# CBASS_CBASS_QOS_45D20000h register map
Vendor: Texas Instruments
Peripheral module from a debugger description file (folder AM275x).
Registers are 32-bit, read-write, reset 0x0 unless marked. A register's access mark holds for its fields unless they carry their own. Offsets are as the file gives them; lines under a group give offsets from that group; [hi:lo] are bit positions; {n}, {i} and the like mark numbered series; 'fields as' and 'values as' point back to an identical list; <NAME> marks a mode.

## cbass_qos
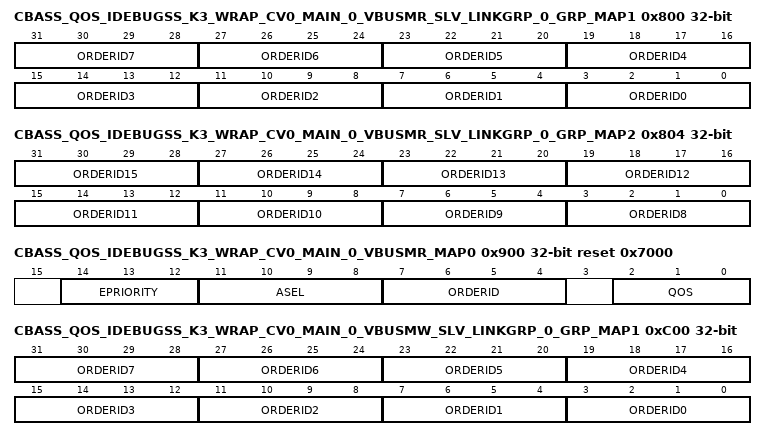
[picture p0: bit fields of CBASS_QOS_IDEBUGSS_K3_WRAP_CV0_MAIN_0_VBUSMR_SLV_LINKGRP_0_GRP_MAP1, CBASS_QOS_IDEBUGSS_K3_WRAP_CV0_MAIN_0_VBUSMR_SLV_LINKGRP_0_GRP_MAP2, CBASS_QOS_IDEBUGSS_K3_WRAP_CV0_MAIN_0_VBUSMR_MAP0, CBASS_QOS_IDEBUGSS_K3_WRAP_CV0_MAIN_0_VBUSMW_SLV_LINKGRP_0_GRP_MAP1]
0x800 CBASS_QOS_IDEBUGSS_K3_WRAP_CV0_MAIN_0_VBUSMR_SLV_LINKGRP_0_GRP_MAP1 — The Group Map Register defines the final orderid for the initiator Idebugss_k3_wrap_cv0_main_0.vbusmr for group slv_linkgrp_0.
  [4n+3:4n] ORDERID{n} (n=0..7) — orderid signal for {n}. Reset Source: domain_default_rst_mod_g_rst_n
0x804 CBASS_QOS_IDEBUGSS_K3_WRAP_CV0_MAIN_0_VBUSMR_SLV_LINKGRP_0_GRP_MAP2 — The Group Map Register defines the final orderid for the initiator Idebugss_k3_wrap_cv0_main_0.vbusmr for group slv_linkgrp_0.
  [4n-29:4n-32] ORDERID{n} (n=8..15) — orderid signal for {n}. Reset Source: domain_default_rst_mod_g_rst_n
0x900 CBASS_QOS_IDEBUGSS_K3_WRAP_CV0_MAIN_0_VBUSMR_MAP0 reset 0x7000 — The Map Register defines the fields for the initiator DEBUGSS0 Read Port per channel
  [14:12] EPRIORITY — epriority signal for channel N.This is the strict priority arbitration priority at the destination Reset Source: domain_default_rst_mod_g_rst_n
  [11:8] ASEL — Only used for PCIe, and cache coherency with A53 ACP. So traffic to MSRAM or DDR with asel set to below values will be routed via A53 cache controller. ASEL=0 | normalASEL=1 | PCIe address space for the entire addressASEL=14 | W | cause L2 cache allocation: for cache warming featureASEL=14 | R | does not cause L2 cache allocationASEL=15 | R/W | does not cause L2 cache allocation Reset Source: domain_default_rst_mod_g_rst_n
  [7:4] ORDERID — orderid signal for channel N.Selects to route for load balancing (0-7 uses one route, 8-15 another).Also used by DDR4/LPDDR4 re-ordering to maximize throughput. Order of transactions is only guaranteed with the same orderid Reset Source: domain_default_rst_mod_g_rst_n
  [2:0] QOS — qos signal for channel N. Reset Source: domain_default_rst_mod_g_rst_n
0xC00 CBASS_QOS_IDEBUGSS_K3_WRAP_CV0_MAIN_0_VBUSMW_SLV_LINKGRP_0_GRP_MAP1 — The Group Map Register defines the final orderid for the initiator Idebugss_k3_wrap_cv0_main_0.vbusmw for group slv_linkgrp_0.
  fields as CBASS_QOS_IDEBUGSS_K3_WRAP_CV0_MAIN_0_VBUSMR_SLV_LINKGRP_0_GRP_MAP1
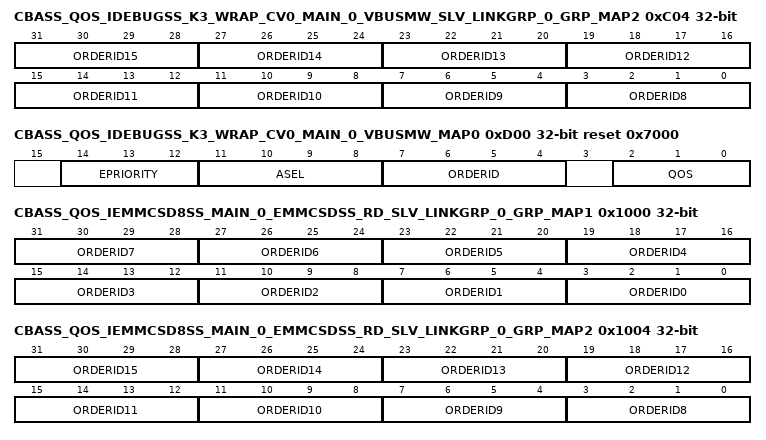
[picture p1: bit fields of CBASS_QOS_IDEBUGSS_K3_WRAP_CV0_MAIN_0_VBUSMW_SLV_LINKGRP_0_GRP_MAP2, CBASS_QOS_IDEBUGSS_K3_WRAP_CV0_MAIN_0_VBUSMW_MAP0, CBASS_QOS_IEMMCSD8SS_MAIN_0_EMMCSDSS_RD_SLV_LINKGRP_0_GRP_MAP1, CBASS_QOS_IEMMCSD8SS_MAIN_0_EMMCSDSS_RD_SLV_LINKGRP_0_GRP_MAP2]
0xC04 CBASS_QOS_IDEBUGSS_K3_WRAP_CV0_MAIN_0_VBUSMW_SLV_LINKGRP_0_GRP_MAP2 — The Group Map Register defines the final orderid for the initiator Idebugss_k3_wrap_cv0_main_0.vbusmw for group slv_linkgrp_0.
  fields as CBASS_QOS_IDEBUGSS_K3_WRAP_CV0_MAIN_0_VBUSMR_SLV_LINKGRP_0_GRP_MAP2
0xD00 CBASS_QOS_IDEBUGSS_K3_WRAP_CV0_MAIN_0_VBUSMW_MAP0 reset 0x7000 — The Map Register defines the fields for the initiator DEBUGSS0 Write Port per channel
  fields as CBASS_QOS_IDEBUGSS_K3_WRAP_CV0_MAIN_0_VBUSMR_MAP0
0x1000 CBASS_QOS_IEMMCSD8SS_MAIN_0_EMMCSDSS_RD_SLV_LINKGRP_0_GRP_MAP1 — The Group Map Register defines the final orderid for the initiator Iemmcsd8ss_main_0.emmcsdss_rd for group slv_linkgrp_0.
  fields as CBASS_QOS_IDEBUGSS_K3_WRAP_CV0_MAIN_0_VBUSMR_SLV_LINKGRP_0_GRP_MAP1
0x1004 CBASS_QOS_IEMMCSD8SS_MAIN_0_EMMCSDSS_RD_SLV_LINKGRP_0_GRP_MAP2 — The Group Map Register defines the final orderid for the initiator Iemmcsd8ss_main_0.emmcsdss_rd for group slv_linkgrp_0.
  fields as CBASS_QOS_IDEBUGSS_K3_WRAP_CV0_MAIN_0_VBUSMR_SLV_LINKGRP_0_GRP_MAP2
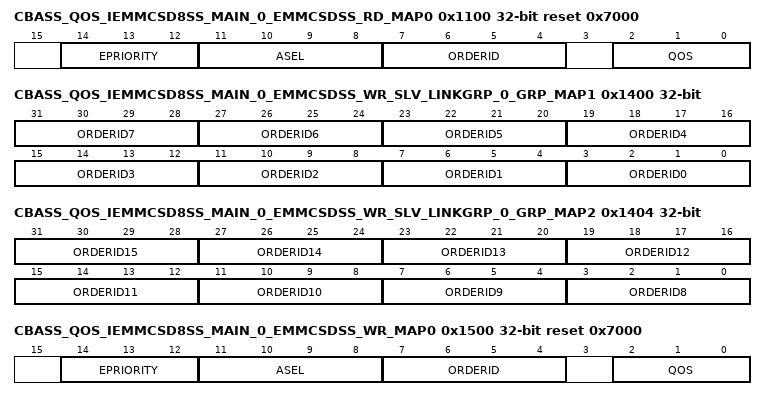
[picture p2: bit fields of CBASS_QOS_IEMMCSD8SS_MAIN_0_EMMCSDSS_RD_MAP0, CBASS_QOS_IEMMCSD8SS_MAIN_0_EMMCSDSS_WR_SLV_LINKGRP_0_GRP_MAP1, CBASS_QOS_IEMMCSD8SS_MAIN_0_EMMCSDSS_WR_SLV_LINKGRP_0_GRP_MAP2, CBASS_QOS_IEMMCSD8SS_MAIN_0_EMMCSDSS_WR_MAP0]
0x1100 CBASS_QOS_IEMMCSD8SS_MAIN_0_EMMCSDSS_RD_MAP0 reset 0x7000 — The Map Register defines the fields for the initiator MMCSD0 Read Port per channel
  fields as CBASS_QOS_IDEBUGSS_K3_WRAP_CV0_MAIN_0_VBUSMR_MAP0
0x1400 CBASS_QOS_IEMMCSD8SS_MAIN_0_EMMCSDSS_WR_SLV_LINKGRP_0_GRP_MAP1 — The Group Map Register defines the final orderid for the initiator Iemmcsd8ss_main_0.emmcsdss_wr for group slv_linkgrp_0.
  fields as CBASS_QOS_IDEBUGSS_K3_WRAP_CV0_MAIN_0_VBUSMR_SLV_LINKGRP_0_GRP_MAP1
0x1404 CBASS_QOS_IEMMCSD8SS_MAIN_0_EMMCSDSS_WR_SLV_LINKGRP_0_GRP_MAP2 — The Group Map Register defines the final orderid for the initiator Iemmcsd8ss_main_0.emmcsdss_wr for group slv_linkgrp_0.
  fields as CBASS_QOS_IDEBUGSS_K3_WRAP_CV0_MAIN_0_VBUSMR_SLV_LINKGRP_0_GRP_MAP2
0x1500 CBASS_QOS_IEMMCSD8SS_MAIN_0_EMMCSDSS_WR_MAP0 reset 0x7000 — The Map Register defines the fields for the initiator MMCSD0 Write Port per channel
  fields as CBASS_QOS_IDEBUGSS_K3_WRAP_CV0_MAIN_0_VBUSMR_MAP0
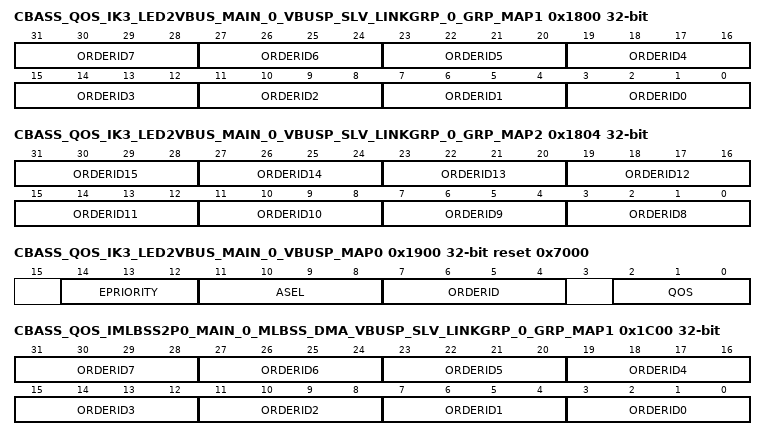
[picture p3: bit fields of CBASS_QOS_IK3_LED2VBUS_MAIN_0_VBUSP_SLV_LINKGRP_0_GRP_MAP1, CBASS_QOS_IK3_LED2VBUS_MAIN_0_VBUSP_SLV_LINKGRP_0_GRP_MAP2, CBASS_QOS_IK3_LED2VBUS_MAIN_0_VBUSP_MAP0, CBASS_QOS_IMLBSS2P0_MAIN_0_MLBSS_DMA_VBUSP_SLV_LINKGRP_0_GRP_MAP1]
0x1800 CBASS_QOS_IK3_LED2VBUS_MAIN_0_VBUSP_SLV_LINKGRP_0_GRP_MAP1 — The Group Map Register defines the final orderid for the initiator Ik3_led2vbus_main_0.vbusp for group slv_linkgrp_0.
  fields as CBASS_QOS_IDEBUGSS_K3_WRAP_CV0_MAIN_0_VBUSMR_SLV_LINKGRP_0_GRP_MAP1
0x1804 CBASS_QOS_IK3_LED2VBUS_MAIN_0_VBUSP_SLV_LINKGRP_0_GRP_MAP2 — The Group Map Register defines the final orderid for the initiator Ik3_led2vbus_main_0.vbusp for group slv_linkgrp_0.
  fields as CBASS_QOS_IDEBUGSS_K3_WRAP_CV0_MAIN_0_VBUSMR_SLV_LINKGRP_0_GRP_MAP2
0x1900 CBASS_QOS_IK3_LED2VBUS_MAIN_0_VBUSP_MAP0 reset 0x7000 — The Map Register defines the fields for the initiator Ik3_led2vbus_main_0.vbusp per channel.
  fields as CBASS_QOS_IDEBUGSS_K3_WRAP_CV0_MAIN_0_VBUSMR_MAP0
0x1C00 CBASS_QOS_IMLBSS2P0_MAIN_0_MLBSS_DMA_VBUSP_SLV_LINKGRP_0_GRP_MAP1 — The Group Map Register defines the final orderid for the initiator Imlbss2p0_main_0.mlbss_dma_vbusp for group slv_linkgrp_0.
  fields as CBASS_QOS_IDEBUGSS_K3_WRAP_CV0_MAIN_0_VBUSMR_SLV_LINKGRP_0_GRP_MAP1
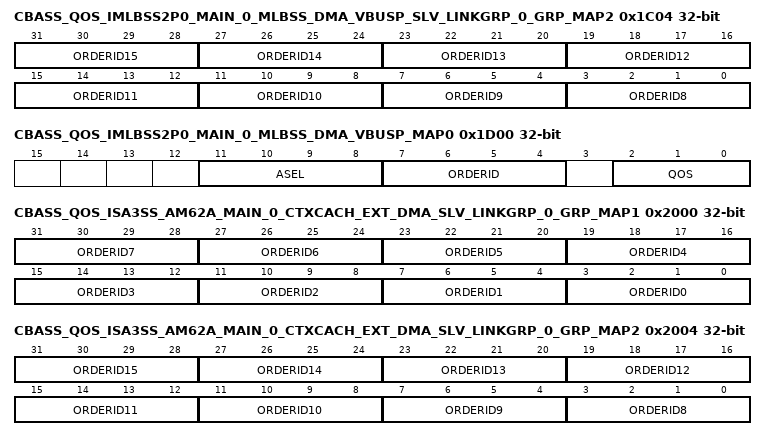
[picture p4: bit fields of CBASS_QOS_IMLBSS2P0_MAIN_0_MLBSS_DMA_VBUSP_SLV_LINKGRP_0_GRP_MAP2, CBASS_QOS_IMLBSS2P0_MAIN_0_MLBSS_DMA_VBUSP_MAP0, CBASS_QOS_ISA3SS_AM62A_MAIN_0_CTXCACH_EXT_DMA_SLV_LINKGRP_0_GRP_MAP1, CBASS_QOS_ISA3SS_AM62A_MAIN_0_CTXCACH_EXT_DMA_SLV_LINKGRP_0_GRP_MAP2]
0x1C04 CBASS_QOS_IMLBSS2P0_MAIN_0_MLBSS_DMA_VBUSP_SLV_LINKGRP_0_GRP_MAP2 — The Group Map Register defines the final orderid for the initiator Imlbss2p0_main_0.mlbss_dma_vbusp for group slv_linkgrp_0.
  fields as CBASS_QOS_IDEBUGSS_K3_WRAP_CV0_MAIN_0_VBUSMR_SLV_LINKGRP_0_GRP_MAP2
0x1D00 CBASS_QOS_IMLBSS2P0_MAIN_0_MLBSS_DMA_VBUSP_MAP0 — The Map Register defines the fields for the initiator Imlbss2p0_main_0.mlbss_dma_vbusp per channel.
  [11:8] ASEL — Only used for PCIe, and cache coherency with A53 ACP. So traffic to MSRAM or DDR with asel set to below values will be routed via A53 cache controller. ASEL=0 | normalASEL=1 | PCIe address space for the entire addressASEL=14 | W | cause L2 cache allocation: for cache warming featureASEL=14 | R | does not cause L2 cache allocationASEL=15 | R/W | does not cause L2 cache allocation Reset Source: domain_default_rst_mod_g_rst_n
  [7:4] ORDERID — orderid signal for channel N.Selects to route for load balancing (0-7 uses one route, 8-15 another).Also used by DDR4/LPDDR4 re-ordering to maximize throughput. Order of transactions is only guaranteed with the same orderid Reset Source: domain_default_rst_mod_g_rst_n
  [2:0] QOS — qos signal for channel N. Reset Source: domain_default_rst_mod_g_rst_n
0x2000 CBASS_QOS_ISA3SS_AM62A_MAIN_0_CTXCACH_EXT_DMA_SLV_LINKGRP_0_GRP_MAP1 — The Group Map Register defines the final orderid for the initiator Isa3ss_am62a_main_0.ctxcach_ext_dma for group slv_linkgrp_0.
  fields as CBASS_QOS_IDEBUGSS_K3_WRAP_CV0_MAIN_0_VBUSMR_SLV_LINKGRP_0_GRP_MAP1
0x2004 CBASS_QOS_ISA3SS_AM62A_MAIN_0_CTXCACH_EXT_DMA_SLV_LINKGRP_0_GRP_MAP2 — The Group Map Register defines the final orderid for the initiator Isa3ss_am62a_main_0.ctxcach_ext_dma for group slv_linkgrp_0.
  fields as CBASS_QOS_IDEBUGSS_K3_WRAP_CV0_MAIN_0_VBUSMR_SLV_LINKGRP_0_GRP_MAP2
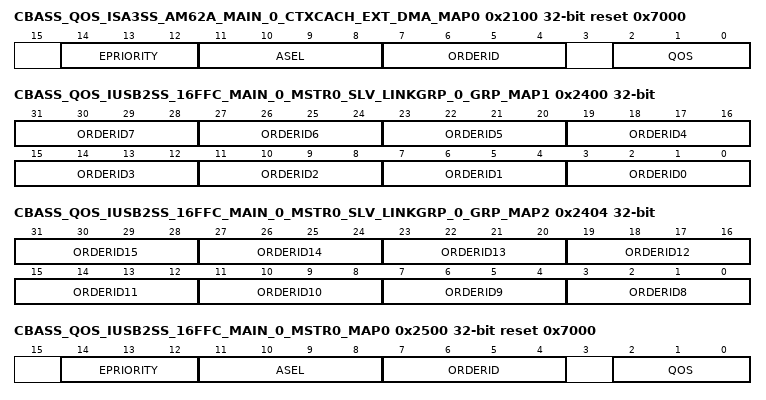
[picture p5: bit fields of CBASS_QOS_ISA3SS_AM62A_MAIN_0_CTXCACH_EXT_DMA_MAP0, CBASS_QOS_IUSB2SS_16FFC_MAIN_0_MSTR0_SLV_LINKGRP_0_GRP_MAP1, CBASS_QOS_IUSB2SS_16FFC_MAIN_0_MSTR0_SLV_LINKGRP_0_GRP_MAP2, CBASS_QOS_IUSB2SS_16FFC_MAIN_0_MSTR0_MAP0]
0x2100 CBASS_QOS_ISA3SS_AM62A_MAIN_0_CTXCACH_EXT_DMA_MAP0 reset 0x7000 — The Map Register defines the fields for the initiator Isa3ss_am62a_main_0.ctxcach_ext_dma per channel.
  fields as CBASS_QOS_IDEBUGSS_K3_WRAP_CV0_MAIN_0_VBUSMR_MAP0
0x2400 CBASS_QOS_IUSB2SS_16FFC_MAIN_0_MSTR0_SLV_LINKGRP_0_GRP_MAP1 — The Group Map Register defines the final orderid for the initiator Iusb2ss_16ffc_main_0.mstr0 for group slv_linkgrp_0.
  fields as CBASS_QOS_IDEBUGSS_K3_WRAP_CV0_MAIN_0_VBUSMR_SLV_LINKGRP_0_GRP_MAP1
0x2404 CBASS_QOS_IUSB2SS_16FFC_MAIN_0_MSTR0_SLV_LINKGRP_0_GRP_MAP2 — The Group Map Register defines the final orderid for the initiator Iusb2ss_16ffc_main_0.mstr0 for group slv_linkgrp_0.
  fields as CBASS_QOS_IDEBUGSS_K3_WRAP_CV0_MAIN_0_VBUSMR_SLV_LINKGRP_0_GRP_MAP2
0x2500 CBASS_QOS_IUSB2SS_16FFC_MAIN_0_MSTR0_MAP0 reset 0x7000 — The Map Register defines the fields for the initiator USB0 Read Port per channel
  fields as CBASS_QOS_IDEBUGSS_K3_WRAP_CV0_MAIN_0_VBUSMR_MAP0
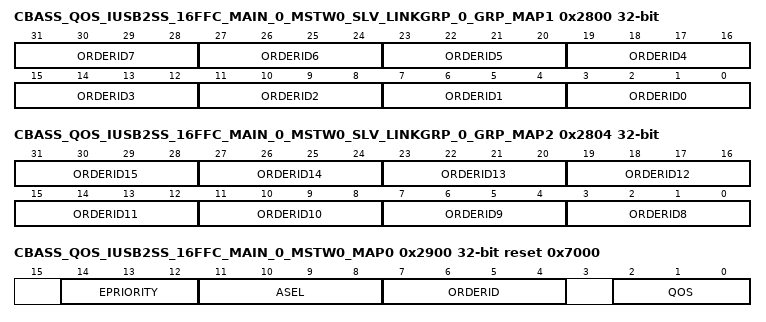
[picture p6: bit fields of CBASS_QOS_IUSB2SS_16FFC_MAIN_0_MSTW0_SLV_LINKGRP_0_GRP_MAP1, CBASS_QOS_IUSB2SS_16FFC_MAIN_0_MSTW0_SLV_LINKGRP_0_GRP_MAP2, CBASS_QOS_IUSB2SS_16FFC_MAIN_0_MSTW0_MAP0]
0x2800 CBASS_QOS_IUSB2SS_16FFC_MAIN_0_MSTW0_SLV_LINKGRP_0_GRP_MAP1 — The Group Map Register defines the final orderid for the initiator Iusb2ss_16ffc_main_0.mstw0 for group slv_linkgrp_0.
  fields as CBASS_QOS_IDEBUGSS_K3_WRAP_CV0_MAIN_0_VBUSMR_SLV_LINKGRP_0_GRP_MAP1
0x2804 CBASS_QOS_IUSB2SS_16FFC_MAIN_0_MSTW0_SLV_LINKGRP_0_GRP_MAP2 — The Group Map Register defines the final orderid for the initiator Iusb2ss_16ffc_main_0.mstw0 for group slv_linkgrp_0.
  fields as CBASS_QOS_IDEBUGSS_K3_WRAP_CV0_MAIN_0_VBUSMR_SLV_LINKGRP_0_GRP_MAP2
0x2900 CBASS_QOS_IUSB2SS_16FFC_MAIN_0_MSTW0_MAP0 reset 0x7000 — The Map Register defines the fields for the initiator USB0 Write Port per channel
  fields as CBASS_QOS_IDEBUGSS_K3_WRAP_CV0_MAIN_0_VBUSMR_MAP0
